# LPC54S018M register map
Vendor: nxp.com; File version: 1.0
CPU: CM4 r0p1, little endian, MPU, FPU, VTOR, 3 interrupt priority bits
Registers are 32-bit, read-write, reset 0x0 unless marked. A register's access mark holds for its fields unless they carry their own. Offsets are from the block's base; [hi:lo] are bit positions; {n}, {i} and the like mark numbered series; 'fields as' and 'values as' point back to an identical list.

## IOCON — LPC5411x I/O pin configuration (IOCON)
Base 0x40001000
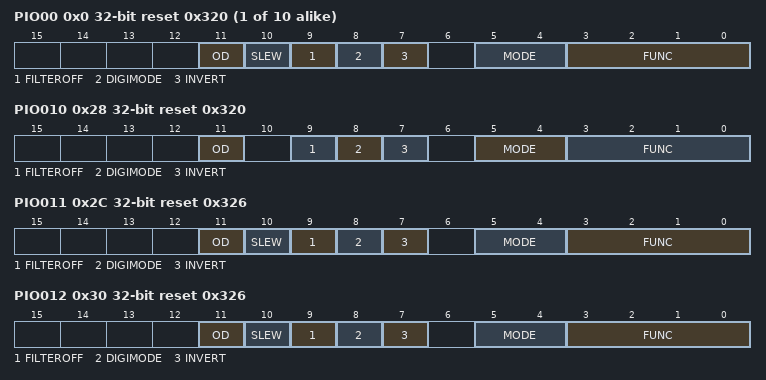
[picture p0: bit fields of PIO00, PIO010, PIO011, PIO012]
{0x0+4i} PIO{i:02} reset 0x320 (i=0..9) — Digital I/O control for port 0 pins PIO0_{i}
  [11] OD — Controls open-drain mode.
    0=NORMAL (Normal. Normal push-pull output); 1=OPEN_DRAIN (Open-drain. Simulated open-drain output (high drive disabled).)
  [10] SLEW — Driver slew rate.
    0=STANDARD (Standard mode, output slew rate control is enabled. More outputs can be switched simultaneously.); 1=FAST (Fast mode, slew rate control is disabled. Refer to the appropriate specific device data sheet for details.)
  [9] FILTEROFF — Controls input glitch filter.
    0=ENABLED (Filter enabled. Noise pulses below approximately 10 ns are filtered out.); 1=DISABLED (Filter disabled. No input filtering is done.)
  [8] DIGIMODE — Select Analog/Digital mode.
    0=ANALOG (Analog mode.); 1=DIGITAL (Digital mode.)
  [7] INVERT — Input polarity.
    0=DISABLED (Disabled. Input function is not inverted.); 1=ENABLED (Enabled. Input is function inverted.)
  [5:4] MODE — Selects function mode (on-chip pull-up/pull-down resistor control).
    0=INACTIVE (Inactive. Inactive (no pull-down/pull-up resistor enabled).); 1=PULL_DOWN (Pull-down. Pull-down resistor enabled.); 2=PULL_UP (Pull-up. Pull-up resistor enabled.); 3=REPEATER (Repeater. Repeater mode.)
  [3:0] FUNC — Selects pin function.
    {v}=ALT{v} (Alternative connection {v}.) (v=0..10)
0x28 PIO010 reset 0x320 — Digital I/O control for port 0 pins PIO0_10
  [11] OD — Controls open-drain mode.
    values as PIO00.OD
  [9] FILTEROFF — Controls input glitch filter.
    values as PIO00.FILTEROFF
  [8] DIGIMODE — Select Analog/Digital mode.
    0=ANALOG (Analog mode.); 1=DIGITAL (Digital mode.)
  [7] INVERT — Input polarity.
    values as PIO00.INVERT
  [5:4] MODE — Selects function mode (on-chip pull-up/pull-down resistor control).
    values as PIO00.MODE
  [3:0] FUNC — Selects pin function.
    {v}=ALT{v} (Alternative connection {v}.) (v=0..10)
0x2C PIO011 reset 0x326 — Digital I/O control for port 0 pins PIO0_11
  fields as PIO00
0x30 PIO012 reset 0x326 — Digital I/O control for port 0 pins PIO0_12
  fields as PIO00
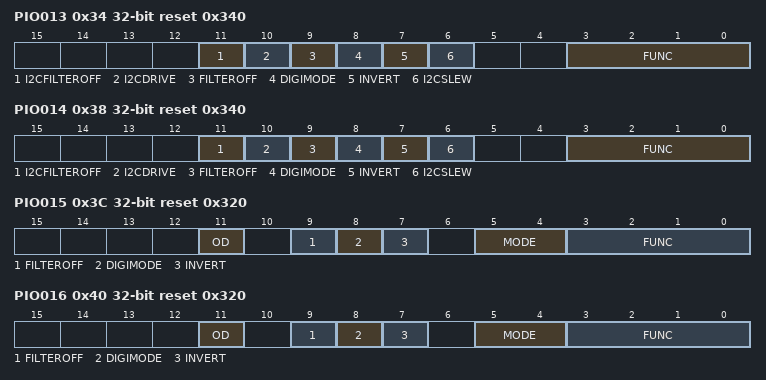
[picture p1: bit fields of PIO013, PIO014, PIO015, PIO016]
0x34 PIO013 reset 0x340 — Digital I/O control for port 0 pins PIO0_13
  [11] I2CFILTEROFF — Configures I2C features for standard mode, fast mode, and Fast Mode Plus operation.
    0=ENABLED (Enabled. I2C 50 ns glitch filter enabled.); 1=DISABLED (Disabled. I2C 50 ns glitch filter disabled.)
  [10] I2CDRIVE — Controls the current sink capability of the pin.
    0=LOW (Low drive. Output drive sink is 4 mA. This is sufficient for standard and fast mode I2C.); 1=HIGH (High drive. Output drive sink is 20 mA. This is needed for Fast Mode Plus I 2C. Refer to the appropriate specific device data sheet for details.)
  [9] FILTEROFF — Controls input glitch filter.
    values as PIO00.FILTEROFF
  [8] DIGIMODE — Select Analog/Digital mode.
    0=ANALOG (Analog mode.); 1=DIGITAL (Digital mode.)
  [7] INVERT — Input polarity.
    values as PIO00.INVERT
  [6] I2CSLEW — Controls slew rate of I2C pad.
    0=I2C_MODE; 1=GPIO_MODE
  [3:0] FUNC — Selects pin function.
    {v}=ALT{v} (Alternative connection {v}.) (v=0..10)
0x38 PIO014 reset 0x340 — Digital I/O control for port 0 pins PIO0_14
  fields as PIO013
0x3C PIO015 reset 0x320 — Digital I/O control for port 0 pins PIO0_15
  fields as PIO010
0x40 PIO016 reset 0x320 — Digital I/O control for port 0 pins PIO0_16
  fields as PIO010
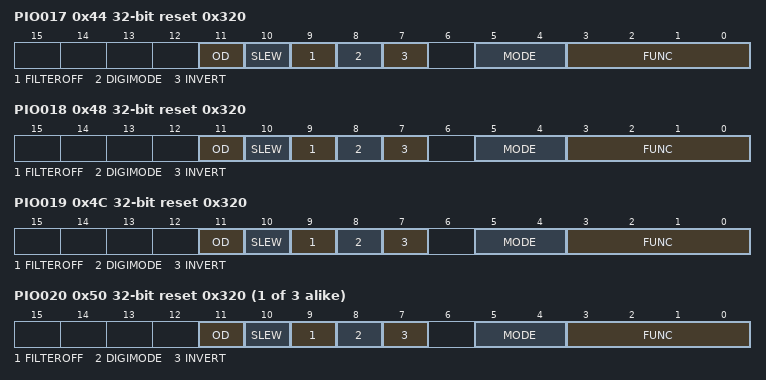
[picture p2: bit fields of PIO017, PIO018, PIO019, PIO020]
0x44 PIO017 reset 0x320 — Digital I/O control for port 0 pins PIO0_17
  fields as PIO00
0x48 PIO018 reset 0x320 — Digital I/O control for port 0 pins PIO0_18
  fields as PIO00
0x4C PIO019 reset 0x320 — Digital I/O control for port 0 pins PIO0_19
  fields as PIO00
{0x0+4i} PIO{i:03} reset 0x320 (i=20..22) — Digital I/O control for port 0 pins PIO0_{i}
  fields as PIO00
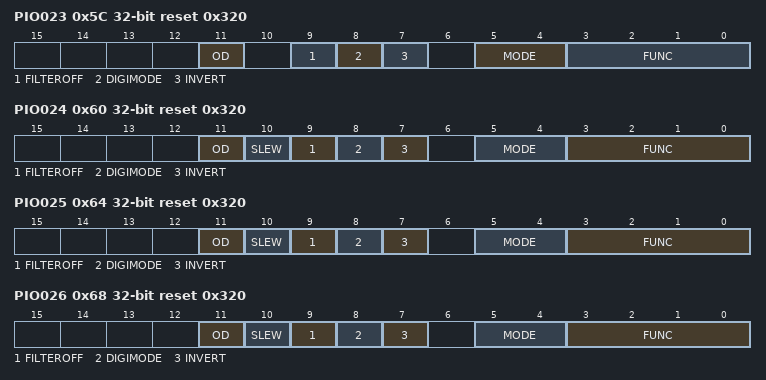
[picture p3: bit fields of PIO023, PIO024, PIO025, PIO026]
0x5C PIO023 reset 0x320 — Digital I/O control for port 0 pins PIO0_23
  fields as PIO010
0x60 PIO024 reset 0x320 — Digital I/O control for port 0 pins PIO0_24
  fields as PIO00
0x64 PIO025 reset 0x320 — Digital I/O control for port 0 pins PIO0_25
  fields as PIO00
0x68 PIO026 reset 0x320 — Digital I/O control for port 0 pins PIO0_26
  fields as PIO00
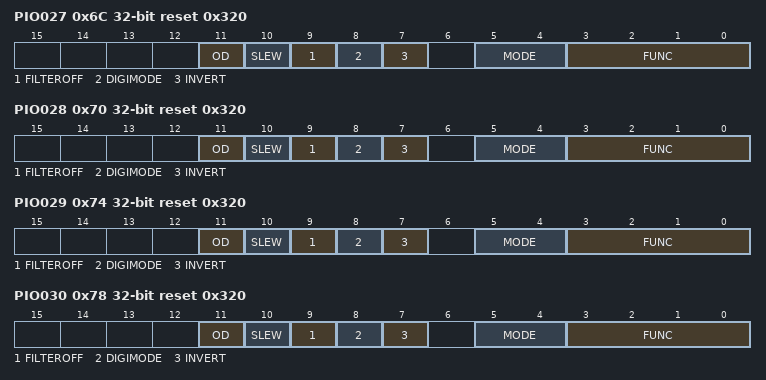
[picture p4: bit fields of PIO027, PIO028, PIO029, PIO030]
0x6C PIO027 reset 0x320 — Digital I/O control for port 0 pins PIO0_27
  fields as PIO00
0x70 PIO028 reset 0x320 — Digital I/O control for port 0 pins PIO0_28
  fields as PIO00
0x74 PIO029 reset 0x320 — Digital I/O control for port 0 pins PIO0_29
  fields as PIO00
0x78 PIO030 reset 0x320 — Digital I/O control for port 0 pins PIO0_30
  fields as PIO00
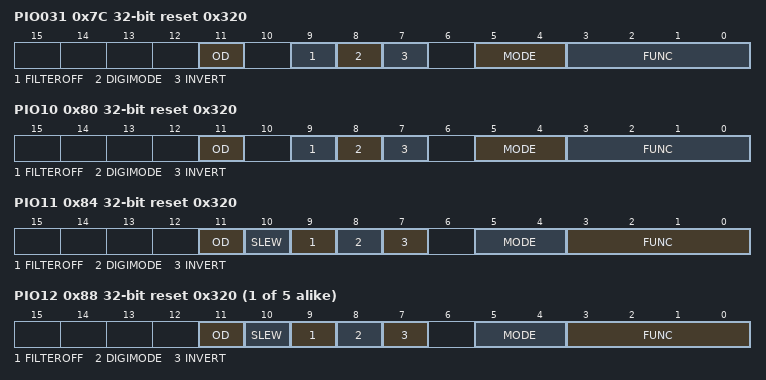
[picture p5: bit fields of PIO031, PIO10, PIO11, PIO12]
0x7C PIO031 reset 0x320 — Digital I/O control for port 0 pins PIO0_31
  fields as PIO010
0x80 PIO10 reset 0x320 — Digital I/O control for port 1 pins PIO1_0
  fields as PIO010
0x84 PIO11 reset 0x320 — Digital I/O control for port 1 pins PIO1_1
  fields as PIO00
{0x58+4i} PIO{i} reset 0x320 (i=12..16) — Digital I/O control for port 1 pins PIO1_{i-10}
  fields as PIO00
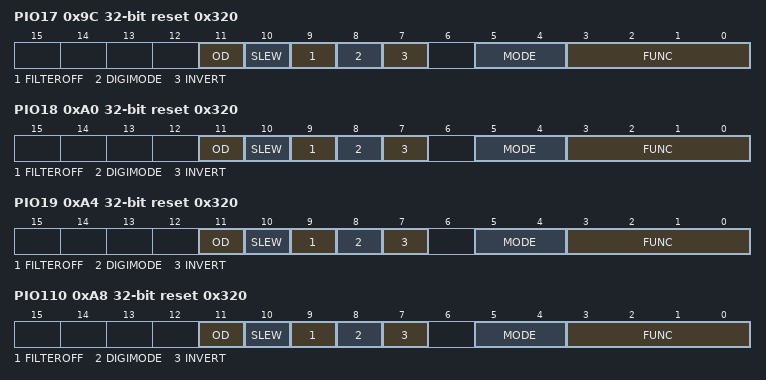
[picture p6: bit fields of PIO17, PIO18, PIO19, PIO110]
0x9C PIO17 reset 0x320 — Digital I/O control for port 1 pins PIO1_7
  fields as PIO00
0xA0 PIO18 reset 0x320 — Digital I/O control for port 1 pins PIO1_8
  fields as PIO00
0xA4 PIO19 reset 0x320 — Digital I/O control for port 1 pins PIO1_9
  fields as PIO00
0xA8 PIO110 reset 0x320 — Digital I/O control for port 1 pins PIO1_10
  fields as PIO00
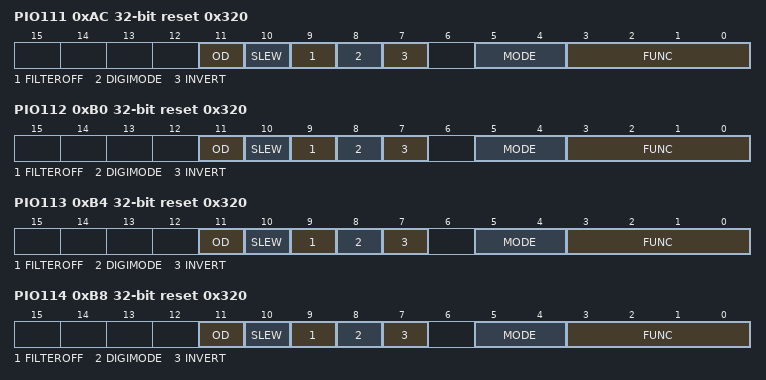
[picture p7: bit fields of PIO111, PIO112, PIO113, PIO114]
0xAC PIO111 reset 0x320 — Digital I/O control for port 1 pins PIO1_11
  fields as PIO00
0xB0 PIO112 reset 0x320 — Digital I/O control for port 1 pins PIO1_12
  fields as PIO00
0xB4 PIO113 reset 0x320 — Digital I/O control for port 1 pins PIO1_13
  fields as PIO00
0xB8 PIO114 reset 0x320 — Digital I/O control for port 1 pins PIO1_14
  fields as PIO00
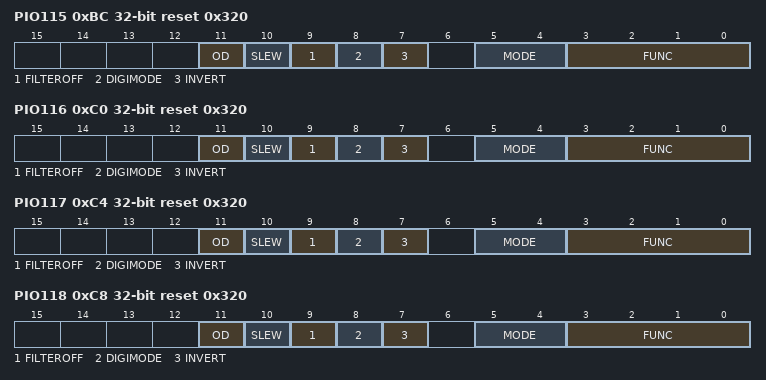
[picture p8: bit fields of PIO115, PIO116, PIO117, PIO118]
0xBC PIO115 reset 0x320 — Digital I/O control for port 1 pins PIO1_15
  fields as PIO00
0xC0 PIO116 reset 0x320 — Digital I/O control for port 1 pins PIO1_16
  fields as PIO00
0xC4 PIO117 reset 0x320 — Digital I/O control for port 1 pins PIO1_17
  fields as PIO00
0xC8 PIO118 reset 0x320 — Digital I/O control for port 1 pins PIO1_18
  fields as PIO00
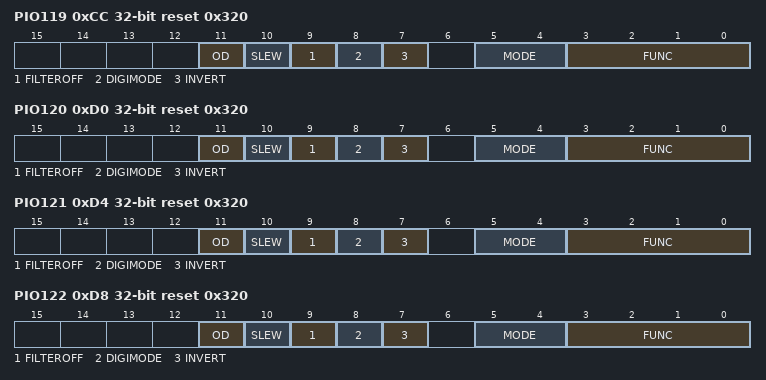
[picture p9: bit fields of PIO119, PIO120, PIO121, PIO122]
0xCC PIO119 reset 0x320 — Digital I/O control for port 1 pins PIO1_19
  fields as PIO00
0xD0 PIO120 reset 0x320 — Digital I/O control for port 1 pins PIO1_20
  fields as PIO00
0xD4 PIO121 reset 0x320 — Digital I/O control for port 1 pins PIO1_21
  fields as PIO00
0xD8 PIO122 reset 0x320 — Digital I/O control for port 1 pins PIO1_22
  fields as PIO00
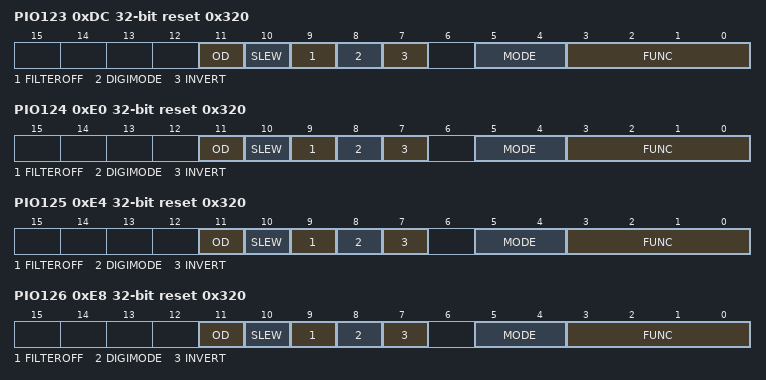
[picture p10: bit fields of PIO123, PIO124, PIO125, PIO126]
0xDC PIO123 reset 0x320 — Digital I/O control for port 1 pins PIO1_23
  fields as PIO00
0xE0 PIO124 reset 0x320 — Digital I/O control for port 1 pins PIO1_24
  fields as PIO00
0xE4 PIO125 reset 0x320 — Digital I/O control for port 1 pins PIO1_25
  fields as PIO00
0xE8 PIO126 reset 0x320 — Digital I/O control for port 1 pins PIO1_26
  fields as PIO00
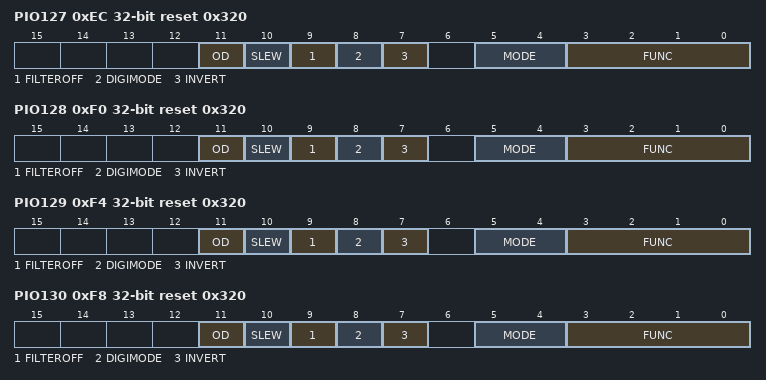
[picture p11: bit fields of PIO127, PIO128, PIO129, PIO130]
0xEC PIO127 reset 0x320 — Digital I/O control for port 1 pins PIO1_27
  fields as PIO00
0xF0 PIO128 reset 0x320 — Digital I/O control for port 1 pins PIO1_28
  fields as PIO00
0xF4 PIO129 reset 0x320 — Digital I/O control for port 1 pins PIO1_29
  fields as PIO00
0xF8 PIO130 reset 0x320 — Digital I/O control for port 1 pins PIO1_30
  fields as PIO00
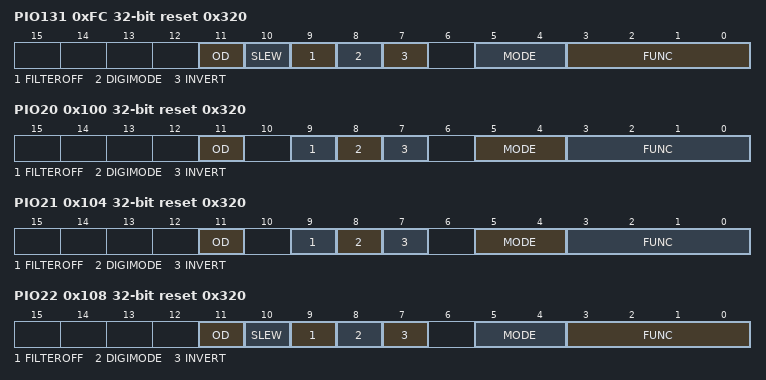
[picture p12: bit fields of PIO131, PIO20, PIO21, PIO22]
0xFC PIO131 reset 0x320 — Digital I/O control for port 1 pins PIO1_31
  fields as PIO00
0x100 PIO20 reset 0x320 — Digital I/O control for port 2 pins PIO2_0
  fields as PIO010
0x104 PIO21 reset 0x320 — Digital I/O control for port 2 pins PIO2_1
  fields as PIO010
0x108 PIO22 reset 0x320 — Digital I/O control for port 2 pins PIO2_2
  fields as PIO00
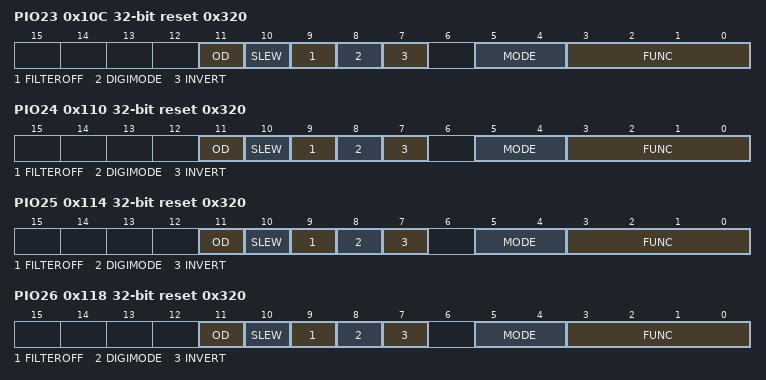
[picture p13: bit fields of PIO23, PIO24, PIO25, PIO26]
0x10C PIO23 reset 0x320 — Digital I/O control for port 2 pins PIO2_3
  fields as PIO00
0x110 PIO24 reset 0x320 — Digital I/O control for port 2 pins PIO2_4
  fields as PIO00
0x114 PIO25 reset 0x320 — Digital I/O control for port 2 pins PIO2_5
  fields as PIO00
0x118 PIO26 reset 0x320 — Digital I/O control for port 2 pins PIO2_6
  fields as PIO00
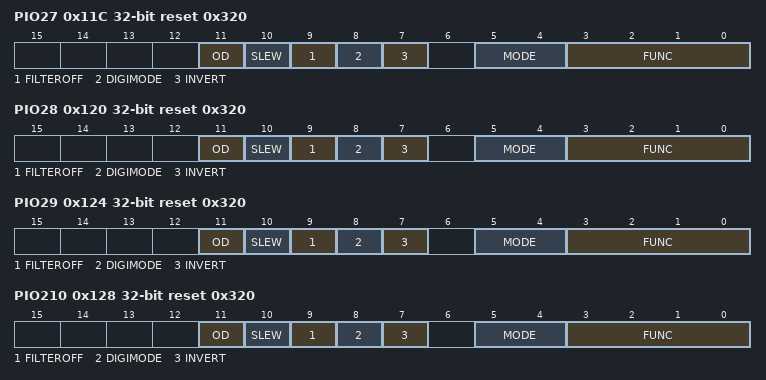
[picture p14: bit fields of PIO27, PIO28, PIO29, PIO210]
0x11C PIO27 reset 0x320 — Digital I/O control for port 2 pins PIO2_7
  fields as PIO00
0x120 PIO28 reset 0x320 — Digital I/O control for port 2 pins PIO2_8
  fields as PIO00
0x124 PIO29 reset 0x320 — Digital I/O control for port 2 pins PIO2_9
  fields as PIO00
0x128 PIO210 reset 0x320 — Digital I/O control for port 2 pins PIO2_10
  fields as PIO00
0x12C PIO211 reset 0x320 — Digital I/O control for port 2 pins PIO2_11
  fields as PIO00
0x130 PIO212 reset 0x320 — Digital I/O control for port 2 pins PIO2_12
  fields as PIO00
0x134 PIO213 reset 0x320 — Digital I/O control for port 2 pins PIO2_13
  fields as PIO00
0x138 PIO214 reset 0x320 — Digital I/O control for port 2 pins PIO2_14
  fields as PIO00
0x13C PIO215 reset 0x320 — Digital I/O control for port 2 pins PIO2_15
  fields as PIO00
0x140 PIO216 reset 0x320 — Digital I/O control for port 2 pins PIO2_16
  fields as PIO00
0x144 PIO217 reset 0x320 — Digital I/O control for port 2 pins PIO2_17
  fields as PIO00
0x148 PIO218 reset 0x320 — Digital I/O control for port 2 pins PIO2_18
  fields as PIO00
0x14C PIO219 reset 0x320 — Digital I/O control for port 2 pins PIO2_19
  fields as PIO00
0x150 PIO220 reset 0x320 — Digital I/O control for port 2 pins PIO2_20
  fields as PIO00
0x154 PIO221 reset 0x320 — Digital I/O control for port 2 pins PIO2_21
  fields as PIO00
0x158 PIO222 reset 0x320 — Digital I/O control for port 2 pins PIO2_22
  fields as PIO00
0x15C PIO223 reset 0x320 — Digital I/O control for port 2 pins PIO2_23
  fields as PIO00
0x160 PIO224 reset 0x320 — Digital I/O control for port 2 pins PIO2_24
  fields as PIO00
0x164 PIO225 reset 0x320 — Digital I/O control for port 2 pins PIO2_25
  fields as PIO00
0x168 PIO226 reset 0x320 — Digital I/O control for port 2 pins PIO2_26
  fields as PIO00
0x16C PIO227 reset 0x320 — Digital I/O control for port 2 pins PIO2_27
  fields as PIO00
0x170 PIO228 reset 0x320 — Digital I/O control for port 2 pins PIO2_28
  fields as PIO00
0x174 PIO229 reset 0x320 — Digital I/O control for port 2 pins PIO2_29
  fields as PIO00
0x178 PIO230 reset 0x320 — Digital I/O control for port 2 pins PIO2_30
  fields as PIO00
0x17C PIO231 reset 0x320 — Digital I/O control for port 2 pins PIO2_31
  fields as PIO00
{0x108+4i} PIO{i} reset 0x320 (i=30..39) — Digital I/O control for port 3 pins PIO3_{i-30}
  fields as PIO00
0x1A8 PIO310 reset 0x320 — Digital I/O control for port 3 pins PIO3_10
  fields as PIO00
0x1AC PIO311 reset 0x320 — Digital I/O control for port 3 pins PIO3_11
  fields as PIO00
0x1B0 PIO312 reset 0x320 — Digital I/O control for port 3 pins PIO3_12
  fields as PIO00
0x1B4 PIO313 reset 0x320 — Digital I/O control for port 3 pins PIO3_13
  fields as PIO00
0x1B8 PIO314 reset 0x320 — Digital I/O control for port 3 pins PIO3_14
  fields as PIO00
0x1BC PIO315 reset 0x320 — Digital I/O control for port 3 pins PIO3_15
  fields as PIO00
0x1C0 PIO316 reset 0x320 — Digital I/O control for port 3 pins PIO3_16
  fields as PIO00
0x1C4 PIO317 reset 0x320 — Digital I/O control for port 3 pins PIO3_17
  fields as PIO00
0x1C8 PIO318 reset 0x320 — Digital I/O control for port 3 pins PIO3_18
  fields as PIO00
0x1CC PIO319 reset 0x320 — Digital I/O control for port 3 pins PIO3_19
  fields as PIO00
0x1D0 PIO320 reset 0x320 — Digital I/O control for port 3 pins PIO3_20
  fields as PIO00
0x1D4 PIO321 reset 0x320 — Digital I/O control for port 3 pins PIO3_21
  fields as PIO010
0x1D8 PIO322 reset 0x320 — Digital I/O control for port 3 pins PIO3_22
  fields as PIO010
0x1DC PIO323 reset 0x340 — Digital I/O control for port 3 pins PIO3_23
  fields as PIO013
0x1E0 PIO324 reset 0x340 — Digital I/O control for port 3 pins PIO3_24
  fields as PIO013
0x1E4 PIO325 reset 0x320 — Digital I/O control for port 3 pins PIO3_25
  fields as PIO00
0x1E8 PIO326 reset 0x320 — Digital I/O control for port 3 pins PIO3_26
  fields as PIO00
0x1EC PIO327 reset 0x320 — Digital I/O control for port 3 pins PIO3_27
  fields as PIO00
0x1F0 PIO328 reset 0x320 — Digital I/O control for port 3 pins PIO3_28
  fields as PIO00
0x1F4 PIO329 reset 0x320 — Digital I/O control for port 3 pins PIO3_29
  fields as PIO00
0x1F8 PIO330 reset 0x320 — Digital I/O control for port 3 pins PIO3_30
  fields as PIO00
0x1FC PIO331 reset 0x320 — Digital I/O control for port 3 pins PIO3_31
  fields as PIO00
{0x160+4i} PIO{i} reset 0x320 (i=40..49) — Digital I/O control for port 4 pins PIO4_{i-40}
  fields as PIO00
0x228 PIO410 reset 0x320 — Digital I/O control for port 4 pins PIO4_10
  fields as PIO00
0x22C PIO411 reset 0x320 — Digital I/O control for port 4 pins PIO4_11
  fields as PIO00
0x230 PIO412 reset 0x320 — Digital I/O control for port 4 pins PIO4_12
  fields as PIO00
0x234 PIO413 reset 0x320 — Digital I/O control for port 4 pins PIO4_13
  fields as PIO00
0x238 PIO414 reset 0x320 — Digital I/O control for port 4 pins PIO4_14
  fields as PIO00
0x23C PIO415 reset 0x320 — Digital I/O control for port 4 pins PIO4_15
  fields as PIO00
0x240 PIO416 reset 0x320 — Digital I/O control for port 4 pins PIO4_16
  fields as PIO00
0x244 PIO417 reset 0x320 — Digital I/O control for port 4 pins PIO4_17
  fields as PIO00
0x248 PIO418 reset 0x320 — Digital I/O control for port 4 pins PIO4_18
  fields as PIO00
0x24C PIO419 reset 0x320 — Digital I/O control for port 4 pins PIO4_19
  fields as PIO00
0x250 PIO420 reset 0x320 — Digital I/O control for port 4 pins PIO4_20
  fields as PIO00
0x254 PIO421 reset 0x320 — Digital I/O control for port 4 pins PIO4_21
  fields as PIO00
0x258 PIO422 reset 0x320 — Digital I/O control for port 4 pins PIO4_22
  fields as PIO00
0x25C PIO423 reset 0x320 — Digital I/O control for port 4 pins PIO4_23
  fields as PIO00
0x260 PIO424 reset 0x320 — Digital I/O control for port 4 pins PIO4_24
  fields as PIO00
0x264 PIO425 reset 0x320 — Digital I/O control for port 4 pins PIO4_25
  fields as PIO00
0x268 PIO426 reset 0x320 — Digital I/O control for port 4 pins PIO4_26
  fields as PIO00
0x26C PIO427 reset 0x320 — Digital I/O control for port 4 pins PIO4_27
  fields as PIO00
0x270 PIO428 reset 0x320 — Digital I/O control for port 4 pins PIO4_28
  fields as PIO00
0x274 PIO429 reset 0x320 — Digital I/O control for port 4 pins PIO4_29
  fields as PIO00
0x278 PIO430 reset 0x320 — Digital I/O control for port 4 pins PIO4_30
  fields as PIO00
0x27C PIO431 reset 0x320 — Digital I/O control for port 4 pins PIO4_31
  fields as PIO00
{0x1B8+4i} PIO{i} reset 0x320 (i=50..59) — Digital I/O control for port 5 pins PIO5_{i-50}
  fields as PIO00
0x2A8 PIO510 reset 0x320 — Digital I/O control for port 5 pins PIO5_10
  fields as PIO00
0x2AC PIO511 reset 0x320 — Digital I/O control for port 5 pins PIO5_11
  fields as PIO00
0x2B0 PIO512 reset 0x320 — Digital I/O control for port 5 pins PIO5_12
  fields as PIO00
0x2B4 PIO513 reset 0x320 — Digital I/O control for port 5 pins PIO5_13
  fields as PIO00
0x2B8 PIO514 reset 0x320 — Digital I/O control for port 5 pins PIO5_14
  fields as PIO00
0x2BC PIO515 reset 0x320 — Digital I/O control for port 5 pins PIO5_15
  fields as PIO00
0x2C0 PIO516 reset 0x320 — Digital I/O control for port 5 pins PIO5_16
  fields as PIO00
0x2C4 PIO517 reset 0x320 — Digital I/O control for port 5 pins PIO5_17
  fields as PIO00
0x2C8 PIO518 reset 0x320 — Digital I/O control for port 5 pins PIO5_18
  fields as PIO00
0x2CC PIO519 reset 0x320 — Digital I/O control for port 5 pins PIO5_19
  fields as PIO00
0x2D0 PIO520 reset 0x320 — Digital I/O control for port 5 pins PIO5_20
  fields as PIO00
0x2D4 PIO521 reset 0x320 — Digital I/O control for port 5 pins PIO5_21
  fields as PIO00
0x2D8 PIO522 reset 0x320 — Digital I/O control for port 5 pins PIO5_22
  fields as PIO00
0x2DC PIO523 reset 0x320 — Digital I/O control for port 5 pins PIO5_23
  fields as PIO00
0x2E0 PIO524 reset 0x320 — Digital I/O control for port 5 pins PIO5_24
  fields as PIO00
0x2E4 PIO525 reset 0x320 — Digital I/O control for port 5 pins PIO5_25
  fields as PIO00
0x2E8 PIO526 reset 0x320 — Digital I/O control for port 5 pins PIO5_26
  fields as PIO00
0x2EC PIO527 reset 0x320 — Digital I/O control for port 5 pins PIO5_27
  fields as PIO00
0x2F0 PIO528 reset 0x320 — Digital I/O control for port 5 pins PIO5_28
  fields as PIO00
0x2F4 PIO529 reset 0x320 — Digital I/O control for port 5 pins PIO5_29
  fields as PIO00
0x2F8 PIO530 reset 0x320 — Digital I/O control for port 5 pins PIO5_30
  fields as PIO00
0x2FC PIO531 reset 0x320 — Digital I/O control for port 5 pins PIO5_31
  fields as PIO00

## Notices in the file
Copyright 2016-2018 NXP
All rights reserved.
SPDX-License-Identifier: BSD-3-Clause
